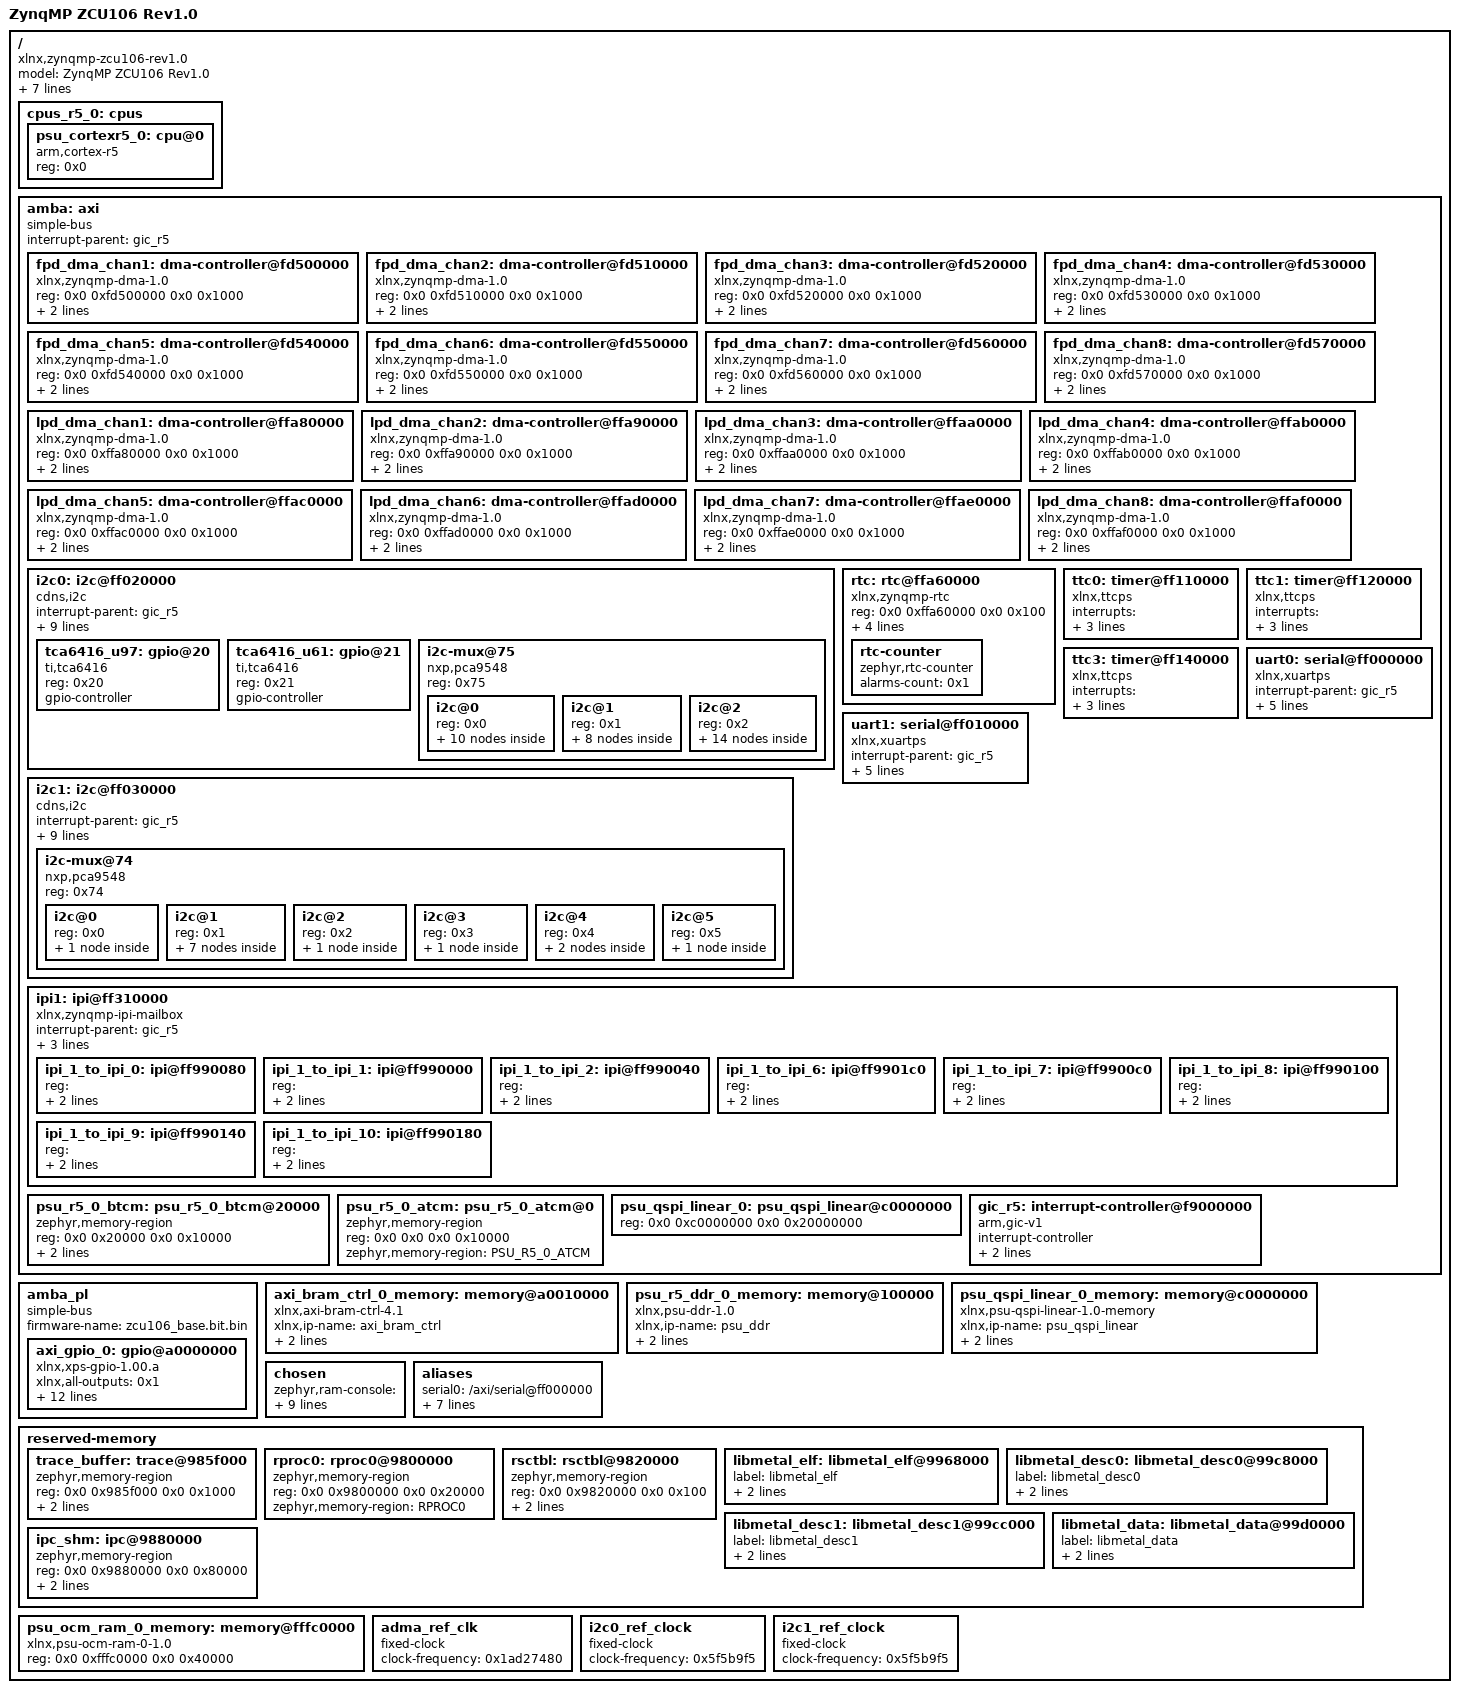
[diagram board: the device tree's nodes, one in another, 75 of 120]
/dts-v1/;
/ {
        compatible = "xlnx,zynqmp-zcu106-rev1.0", "xlnx,zynqmp-zcu106-revA", "xlnx,zynqmp-zcu106", "xlnx,zynqmp";
        #address-cells = <0x2>;
        #size-cells = <0x2>;
        model = "ZynqMP ZCU106 Rev1.0";
        board = "zcu106";
        vivado-version = "2026.2.0";
        device_id = "xczu7ev";
        slrcount = <0x1>;
        family = "ZynqMP";
        speed_grade = "2";
        pruned-sdt = <0x1>;

        cpus_r5_0: cpus {
                phandle = <0xc6>;
                #address-cells = <0x1>;
                #size-cells = <0x0>;

                psu_cortexr5_0: cpu@0 {
                        phandle = <0xc7>;
                        compatible = "arm,cortex-r5", "arm,armv8";
                        device_type = "cpu";
                        reg = <0x0>;
                };
        };

        amba: axi {
                phandle = <0x1>;
                compatible = "simple-bus";
                bootph-all;
                #address-cells = <0x2>;
                #size-cells = <0x2>;
                ranges;
                interrupt-parent = <&gic_r5>;

                fpd_dma_chan1: dma-controller@fd500000 {
                        phandle = <0x43>;
                        compatible = "xlnx,zynqmp-dma-1.0";
                        reg = <0x0 0xfd500000 0x0 0x1000>;
                        interrupts = <0x0 0x7c 0x4 0xa0>;
                        clock-names = "clk_main", "clk_apb";
                        #dma-cells = <0x1>;
                        clocks = <&adma_ref_clk>, <&adma_ref_clk>;
                };

                fpd_dma_chan2: dma-controller@fd510000 {
                        phandle = <0x44>;
                        compatible = "xlnx,zynqmp-dma-1.0";
                        reg = <0x0 0xfd510000 0x0 0x1000>;
                        interrupts = <0x0 0x7d 0x4 0xa0>;
                        clock-names = "clk_main", "clk_apb";
                        #dma-cells = <0x1>;
                        clocks = <&adma_ref_clk>, <&adma_ref_clk>;
                };

                fpd_dma_chan3: dma-controller@fd520000 {
                        phandle = <0x45>;
                        compatible = "xlnx,zynqmp-dma-1.0";
                        reg = <0x0 0xfd520000 0x0 0x1000>;
                        interrupts = <0x0 0x7e 0x4 0xa0>;
                        clock-names = "clk_main", "clk_apb";
                        #dma-cells = <0x1>;
                        clocks = <&adma_ref_clk>, <&adma_ref_clk>;
                };

                fpd_dma_chan4: dma-controller@fd530000 {
                        phandle = <0x46>;
                        compatible = "xlnx,zynqmp-dma-1.0";
                        reg = <0x0 0xfd530000 0x0 0x1000>;
                        interrupts = <0x0 0x7f 0x4 0xa0>;
                        clock-names = "clk_main", "clk_apb";
                        #dma-cells = <0x1>;
                        clocks = <&adma_ref_clk>, <&adma_ref_clk>;
                };

                fpd_dma_chan5: dma-controller@fd540000 {
                        phandle = <0x47>;
                        compatible = "xlnx,zynqmp-dma-1.0";
                        reg = <0x0 0xfd540000 0x0 0x1000>;
                        interrupts = <0x0 0x80 0x4 0xa0>;
                        clock-names = "clk_main", "clk_apb";
                        #dma-cells = <0x1>;
                        clocks = <&adma_ref_clk>, <&adma_ref_clk>;
                };

                fpd_dma_chan6: dma-controller@fd550000 {
                        phandle = <0x48>;
                        compatible = "xlnx,zynqmp-dma-1.0";
                        reg = <0x0 0xfd550000 0x0 0x1000>;
                        interrupts = <0x0 0x81 0x4 0xa0>;
                        clock-names = "clk_main", "clk_apb";
                        #dma-cells = <0x1>;
                        clocks = <&adma_ref_clk>, <&adma_ref_clk>;
                };

                fpd_dma_chan7: dma-controller@fd560000 {
                        phandle = <0x49>;
                        compatible = "xlnx,zynqmp-dma-1.0";
                        reg = <0x0 0xfd560000 0x0 0x1000>;
                        interrupts = <0x0 0x82 0x4 0xa0>;
                        clock-names = "clk_main", "clk_apb";
                        #dma-cells = <0x1>;
                        clocks = <&adma_ref_clk>, <&adma_ref_clk>;
                };

                fpd_dma_chan8: dma-controller@fd570000 {
                        phandle = <0x4a>;
                        compatible = "xlnx,zynqmp-dma-1.0";
                        reg = <0x0 0xfd570000 0x0 0x1000>;
                        interrupts = <0x0 0x83 0x4 0xa0>;
                        clock-names = "clk_main", "clk_apb";
                        #dma-cells = <0x1>;
                        clocks = <&adma_ref_clk>, <&adma_ref_clk>;
                };

                lpd_dma_chan1: dma-controller@ffa80000 {
                        phandle = <0x13>;
                        compatible = "xlnx,zynqmp-dma-1.0";
                        reg = <0x0 0xffa80000 0x0 0x1000>;
                        interrupts = <0x0 0x4d 0x4 0xa0>;
                        clock-names = "clk_main", "clk_apb";
                        #dma-cells = <0x1>;
                        clocks = <&adma_ref_clk>, <&adma_ref_clk>;
                };

                lpd_dma_chan2: dma-controller@ffa90000 {
                        phandle = <0x14>;
                        compatible = "xlnx,zynqmp-dma-1.0";
                        reg = <0x0 0xffa90000 0x0 0x1000>;
                        interrupts = <0x0 0x4e 0x4 0xa0>;
                        clock-names = "clk_main", "clk_apb";
                        #dma-cells = <0x1>;
                        clocks = <&adma_ref_clk>, <&adma_ref_clk>;
                };

                lpd_dma_chan3: dma-controller@ffaa0000 {
                        phandle = <0x15>;
                        compatible = "xlnx,zynqmp-dma-1.0";
                        reg = <0x0 0xffaa0000 0x0 0x1000>;
                        interrupts = <0x0 0x4f 0x4 0xa0>;
                        clock-names = "clk_main", "clk_apb";
                        #dma-cells = <0x1>;
                        clocks = <&adma_ref_clk>, <&adma_ref_clk>;
                };

                lpd_dma_chan4: dma-controller@ffab0000 {
                        phandle = <0x16>;
                        compatible = "xlnx,zynqmp-dma-1.0";
                        reg = <0x0 0xffab0000 0x0 0x1000>;
                        interrupts = <0x0 0x50 0x4 0xa0>;
                        clock-names = "clk_main", "clk_apb";
                        #dma-cells = <0x1>;
                        clocks = <&adma_ref_clk>, <&adma_ref_clk>;
                };

                lpd_dma_chan5: dma-controller@ffac0000 {
                        phandle = <0x17>;
                        compatible = "xlnx,zynqmp-dma-1.0";
                        reg = <0x0 0xffac0000 0x0 0x1000>;
                        interrupts = <0x0 0x51 0x4 0xa0>;
                        clock-names = "clk_main", "clk_apb";
                        #dma-cells = <0x1>;
                        clocks = <&adma_ref_clk>, <&adma_ref_clk>;
                };

                lpd_dma_chan6: dma-controller@ffad0000 {
                        phandle = <0x18>;
                        compatible = "xlnx,zynqmp-dma-1.0";
                        reg = <0x0 0xffad0000 0x0 0x1000>;
                        interrupts = <0x0 0x52 0x4 0xa0>;
                        clock-names = "clk_main", "clk_apb";
                        #dma-cells = <0x1>;
                        clocks = <&adma_ref_clk>, <&adma_ref_clk>;
                };

                lpd_dma_chan7: dma-controller@ffae0000 {
                        phandle = <0x19>;
                        compatible = "xlnx,zynqmp-dma-1.0";
                        reg = <0x0 0xffae0000 0x0 0x1000>;
                        interrupts = <0x0 0x53 0x4 0xa0>;
                        clock-names = "clk_main", "clk_apb";
                        #dma-cells = <0x1>;
                        clocks = <&adma_ref_clk>, <&adma_ref_clk>;
                };

                lpd_dma_chan8: dma-controller@ffaf0000 {
                        phandle = <0x1a>;
                        compatible = "xlnx,zynqmp-dma-1.0";
                        reg = <0x0 0xffaf0000 0x0 0x1000>;
                        interrupts = <0x0 0x54 0x4 0xa0>;
                        clock-names = "clk_main", "clk_apb";
                        #dma-cells = <0x1>;
                        clocks = <&adma_ref_clk>, <&adma_ref_clk>;
                };

                i2c0: i2c@ff020000 {
                        phandle = <0x4d>;
                        compatible = "cdns,i2c";
                        status = "okay";
                        interrupt-parent = <&gic_r5>;
                        interrupts = <0x0 0x11 0x4 0xa0>;
                        clock-frequency = <0x61a80>;
                        reg = <0x0 0xff020000 0x0 0x1000>;
                        #address-cells = <0x1>;
                        #size-cells = <0x0>;
                        fifo-depth = <0x10>;
                        clocks = <&i2c0_ref_clock>;
                        pinctrl-names = "default", "gpio";
                        pinctrl-0 = <0x19>;
                        pinctrl-1 = <0x1a>;
                        scl-gpios = <0xffffffff 0xe 0x6>;
                        sda-gpios = <0xffffffff 0xf 0x6>;

                        tca6416_u97: gpio@20 {
                                phandle = <0x19e>;
                                compatible = "ti,tca6416";
                                reg = <0x20>;
                                gpio-controller;
                                #gpio-cells = <0x2>;
                        };

                        tca6416_u61: gpio@21 {
                                phandle = <0x26>;
                                compatible = "ti,tca6416";
                                reg = <0x21>;
                                gpio-controller;
                                #gpio-cells = <0x2>;
                        };

                        i2c-mux@75 {
                                compatible = "nxp,pca9548";
                                #address-cells = <0x1>;
                                #size-cells = <0x0>;
                                reg = <0x75>;

                                i2c@0 {
                                        #address-cells = <0x1>;
                                        #size-cells = <0x0>;
                                        reg = <0x0>;

                                        u76: ina226@40 {
                                                phandle = <0x19f>;
                                                compatible = "ti,ina226";
                                                #io-channel-cells = <0x1>;
                                                label = "ina226-u76";
                                                reg = <0x40>;
                                                shunt-resistor = <0x1388>;
                                        };

                                        u77: ina226@41 {
                                                phandle = <0x2>;
                                                compatible = "ti,ina226";
                                                #io-channel-cells = <0x1>;
                                                label = "ina226-u77";
                                                reg = <0x41>;
                                                shunt-resistor = <0x1388>;
                                        };

                                        u78: ina226@42 {
                                                phandle = <0x3>;
                                                compatible = "ti,ina226";
                                                #io-channel-cells = <0x1>;
                                                label = "ina226-u78";
                                                reg = <0x42>;
                                                shunt-resistor = <0x1388>;
                                        };

                                        u87: ina226@43 {
                                                phandle = <0x4>;
                                                compatible = "ti,ina226";
                                                #io-channel-cells = <0x1>;
                                                label = "ina226-u87";
                                                reg = <0x43>;
                                                shunt-resistor = <0x1388>;
                                        };

                                        u85: ina226@44 {
                                                phandle = <0x5>;
                                                compatible = "ti,ina226";
                                                #io-channel-cells = <0x1>;
                                                label = "ina226-u85";
                                                reg = <0x44>;
                                                shunt-resistor = <0x1388>;
                                        };

                                        u86: ina226@45 {
                                                phandle = <0x6>;
                                                compatible = "ti,ina226";
                                                #io-channel-cells = <0x1>;
                                                label = "ina226-u86";
                                                reg = <0x45>;
                                                shunt-resistor = <0x1388>;
                                        };

                                        u93: ina226@46 {
                                                phandle = <0x1a0>;
                                                compatible = "ti,ina226";
                                                #io-channel-cells = <0x1>;
                                                label = "ina226-u93";
                                                reg = <0x46>;
                                                shunt-resistor = <0x1388>;
                                        };

                                        u88: ina226@47 {
                                                phandle = <0x8>;
                                                compatible = "ti,ina226";
                                                #io-channel-cells = <0x1>;
                                                label = "ina226-u88";
                                                reg = <0x47>;
                                                shunt-resistor = <0x1388>;
                                        };

                                        u15: ina226@4a {
                                                phandle = <0x1a1>;
                                                compatible = "ti,ina226";
                                                #io-channel-cells = <0x1>;
                                                label = "ina226-u15";
                                                reg = <0x4a>;
                                                shunt-resistor = <0x1388>;
                                        };

                                        u92: ina226@4b {
                                                phandle = <0xa>;
                                                compatible = "ti,ina226";
                                                #io-channel-cells = <0x1>;
                                                label = "ina226-u92";
                                                reg = <0x4b>;
                                                shunt-resistor = <0x1388>;
                                        };
                                };

                                i2c@1 {
                                        #address-cells = <0x1>;
                                        #size-cells = <0x0>;
                                        reg = <0x1>;

                                        u79: ina226@40 {
                                                phandle = <0xb>;
                                                compatible = "ti,ina226";
                                                #io-channel-cells = <0x1>;
                                                label = "ina226-u79";
                                                reg = <0x40>;
                                                shunt-resistor = <0x7d0>;
                                        };

                                        u81: ina226@41 {
                                                phandle = <0xc>;
                                                compatible = "ti,ina226";
                                                #io-channel-cells = <0x1>;
                                                label = "ina226-u81";
                                                reg = <0x41>;
                                                shunt-resistor = <0x1388>;
                                        };

                                        u80: ina226@42 {
                                                phandle = <0xd>;
                                                compatible = "ti,ina226";
                                                #io-channel-cells = <0x1>;
                                                label = "ina226-u80";
                                                reg = <0x42>;
                                                shunt-resistor = <0x1388>;
                                        };

                                        u84: ina226@43 {
                                                phandle = <0xe>;
                                                compatible = "ti,ina226";
                                                #io-channel-cells = <0x1>;
                                                label = "ina226-u84";
                                                reg = <0x43>;
                                                shunt-resistor = <0x1388>;
                                        };

                                        u16: ina226@44 {
                                                phandle = <0xf>;
                                                compatible = "ti,ina226";
                                                #io-channel-cells = <0x1>;
                                                label = "ina226-u16";
                                                reg = <0x44>;
                                                shunt-resistor = <0x1388>;
                                        };

                                        u65: ina226@45 {
                                                phandle = <0x10>;
                                                compatible = "ti,ina226";
                                                #io-channel-cells = <0x1>;
                                                label = "ina226-u65";
                                                reg = <0x45>;
                                                shunt-resistor = <0x1388>;
                                        };

                                        u74: ina226@46 {
                                                phandle = <0x1a2>;
                                                compatible = "ti,ina226";
                                                #io-channel-cells = <0x1>;
                                                label = "ina226-u74";
                                                reg = <0x46>;
                                                shunt-resistor = <0x1388>;
                                        };

                                        u75: ina226@47 {
                                                phandle = <0x12>;
                                                compatible = "ti,ina226";
                                                #io-channel-cells = <0x1>;
                                                label = "ina226-u75";
                                                reg = <0x47>;
                                                shunt-resistor = <0x1388>;
                                        };
                                };

                                i2c@2 {
                                        #address-cells = <0x1>;
                                        #size-cells = <0x0>;
                                        reg = <0x2>;

                                        max15301@a {
                                                compatible = "maxim,max15301";
                                                reg = <0xa>;
                                        };

                                        max15303@b {
                                                compatible = "maxim,max15303";
                                                reg = <0xb>;
                                        };

                                        max15303@10 {
                                                compatible = "maxim,max15303";
                                                reg = <0x10>;
                                        };

                                        max15301@13 {
                                                compatible = "maxim,max15301";
                                                reg = <0x13>;
                                        };

                                        max15303@14 {
                                                compatible = "maxim,max15303";
                                                reg = <0x14>;
                                        };

                                        max15303@15 {
                                                compatible = "maxim,max15303";
                                                reg = <0x15>;
                                        };

                                        max15303@16 {
                                                compatible = "maxim,max15303";
                                                reg = <0x16>;
                                        };

                                        max15303@17 {
                                                compatible = "maxim,max15303";
                                                reg = <0x17>;
                                        };

                                        max15301@18 {
                                                compatible = "maxim,max15301";
                                                reg = <0x18>;
                                        };

                                        max15303@1a {
                                                compatible = "maxim,max15303";
                                                reg = <0x1a>;
                                        };

                                        max15303@1b {
                                                compatible = "maxim,max15303";
                                                reg = <0x1b>;
                                        };

                                        max15303@1d {
                                                compatible = "maxim,max15303";
                                                reg = <0x1d>;
                                        };

                                        max20751@72 {
                                                compatible = "maxim,max20751";
                                                reg = <0x72>;
                                        };

                                        max20751@73 {
                                                compatible = "maxim,max20751";
                                                reg = <0x73>;
                                        };
                                };
                        };
                };

                i2c1: i2c@ff030000 {
                        phandle = <0x4e>;
                        compatible = "cdns,i2c";
                        status = "okay";
                        interrupt-parent = <&gic_r5>;
                        interrupts = <0x0 0x12 0x4 0xa0>;
                        clock-frequency = <0x61a80>;
                        reg = <0x0 0xff030000 0x0 0x1000>;
                        #address-cells = <0x1>;
                        #size-cells = <0x0>;
                        fifo-depth = <0x10>;
                        clocks = <&i2c1_ref_clock>;
                        pinctrl-names = "default", "gpio";
                        pinctrl-0 = <0x1b>;
                        pinctrl-1 = <0x1c>;
                        scl-gpios = <0xffffffff 0x10 0x6>;
                        sda-gpios = <0xffffffff 0x11 0x6>;

                        i2c-mux@74 {
                                compatible = "nxp,pca9548";
                                #address-cells = <0x1>;
                                #size-cells = <0x0>;
                                reg = <0x74>;

                                i2c@0 {
                                        #address-cells = <0x1>;
                                        #size-cells = <0x0>;
                                        reg = <0x0>;

                                        eeprom: eeprom@54 {
                                                phandle = <0x27>;
                                                compatible = "atmel,24c08";
                                                label = "eeprom_zcu106a";
                                                reg = <0x54>;
                                        };
                                };

                                i2c@1 {
                                        #address-cells = <0x1>;
                                        #size-cells = <0x0>;
                                        reg = <0x1>;

                                        si5341: clock-generator@36 {
                                                phandle = <0x1f>;
                                                compatible = "silabs,si5341";
                                                reg = <0x36>;
                                                #clock-cells = <0x2>;
                                                #address-cells = <0x1>;
                                                #size-cells = <0x0>;
                                                clock-names;
                                                clock-output-names = "si5341";

                                                si5341_0: out@0 {
                                                        phandle = <0x28>;
                                                        reg = <0x0>;
                                                        always-on;
                                                };

                                                si5341_2: out@2 {
                                                        phandle = <0x29>;
                                                        reg = <0x2>;
                                                        always-on;
                                                };

                                                si5341_3: out@3 {
                                                        phandle = <0x2a>;
                                                        reg = <0x3>;
                                                        always-on;
                                                };

                                                si5341_6: out@6 {
                                                        phandle = <0x2b>;
                                                        reg = <0x6>;
                                                        always-on;
                                                };

                                                si5341_7: out@7 {
                                                        phandle = <0x2c>;
                                                        reg = <0x7>;
                                                        always-on;
                                                };

                                                si5341_9: out@9 {
                                                        phandle = <0x2d>;
                                                        reg = <0x9>;
                                                        always-on;
                                                };
                                        };
                                };

                                i2c@2 {
                                        #address-cells = <0x1>;
                                        #size-cells = <0x0>;
                                        reg = <0x2>;

                                        si570_1: clock-generator@5d {
                                                phandle = <0x2e>;
                                                #clock-cells = <0x0>;
                                                compatible = "silabs,si570";
                                                reg = <0x5d>;
                                                temperature-stability = <0x32>;
                                                factory-fout = <0x11e1a300>;
                                                clock-frequency = <0x11e1a300>;
                                                clock-output-names = "si570_user";
                                        };
                                };

                                i2c@3 {
                                        #address-cells = <0x1>;
                                        #size-cells = <0x0>;
                                        reg = <0x3>;

                                        si570_2: clock-generator@5d {
                                                phandle = <0x2f>;
                                                #clock-cells = <0x0>;
                                                compatible = "silabs,si570";
                                                reg = <0x5d>;
                                                temperature-stability = <0x32>;
                                                factory-fout = <0x9502f90>;
                                                clock-frequency = <0x9502f90>;
                                                clock-output-names = "si570_mgt";
                                        };
                                };

                                i2c@4 {
                                        #address-cells = <0x1>;
                                        #size-cells = <0x0>;
                                        reg = <0x4>;

                                        si5328: clock-generator@69 {
                                                phandle = <0x30>;
                                                compatible = "silabs,si5328";
                                                reg = <0x69>;
                                                #address-cells = <0x1>;
                                                #size-cells = <0x0>;
                                                #clock-cells = <0x1>;
                                                clock-names;
                                                clock-output-names = "si5328";

                                                si5328_clk: clk0@0 {
                                                        phandle = <0x31>;
                                                        reg = <0x0>;
                                                        clock-frequency = <0x19bfcc0>;
                                                };
                                        };
                                };

                                i2c@5 {
                                        #address-cells = <0x1>;
                                        #size-cells = <0x0>;
                                        reg = <0x5>;

                                        temp@4c {
                                                compatible = "national,lm96163";
                                                reg = <0x4c>;
                                        };
                                };
                        };
                };

                rtc: rtc@ffa60000 {
                        phandle = <0x65>;
                        compatible = "xlnx,zynqmp-rtc";
                        status = "okay";
                        reg = <0x0 0xffa60000 0x0 0x100>;
                        interrupt-parent = <&gic_r5>;
                        interrupts = <0x0 0x1a 0x4 0xa0 0x0 0x1b 0x4 0xa0>;
                        interrupt-names = "alarm", "sec";
                        clock-frequency = <0x8000>;

                        rtc-counter {
                                compatible = "zephyr,rtc-counter";
                                status = "okay";
                                alarms-count = <0x1>;
                        };
                };

                ttc0: timer@ff110000 {
                        phandle = <0x6c>;
                        compatible = "xlnx,ttcps";
                        status = "okay";
                        interrupts = <0x0 0x24 0x4 0xa0 0x0 0x25 0x4 0xa0 0x0 0x26 0x4 0xa0>;
                        reg = <0x0 0xff110000 0x0 0x1000>;
                        interrupt-names = "irq_0", "irq_1", "irq_2";
                        clock-frequency = <0x5f5e100>;
                };

                ttc1: timer@ff120000 {
                        phandle = <0x6d>;
                        compatible = "xlnx,ttcps";
                        status = "okay";
                        interrupts = <0x0 0x27 0x4 0xa0 0x0 0x28 0x4 0xa0 0x0 0x29 0x4 0xa0>;
                        reg = <0x0 0xff120000 0x0 0x1000>;
                        interrupt-names = "irq_0", "irq_1", "irq_2";
                        clock-frequency = <0x5f5e100>;
                };

                ttc3: timer@ff140000 {
                        phandle = <0x6f>;
                        compatible = "xlnx,ttcps";
                        status = "okay";
                        interrupts = <0x0 0x2d 0x4 0xa0 0x0 0x2e 0x4 0xa0 0x0 0x2f 0x4 0xa0>;
                        reg = <0x0 0xff140000 0x0 0x1000>;
                        interrupt-names = "irq_0", "irq_1", "irq_2";
                        clock-frequency = <0x5f5e100>;
                };

                uart0: serial@ff000000 {
                        phandle = <0x70>;
                        compatible = "xlnx,xuartps";
                        interrupt-parent = <&gic_r5>;
                        interrupts = <0x0 0x15 0x4 0xa0>;
                        reg = <0x0 0xff000000 0x0 0x1000>;
                        clock-frequency = <0x5f5b9f5>;
                        current-speed = <0x1c200>;
                        pinctrl-names = "default";
                        pinctrl-0 = <0x21>;
                };

                uart1: serial@ff010000 {
                        phandle = <0x71>;
                        compatible = "xlnx,xuartps";
                        interrupt-parent = <&gic_r5>;
                        interrupts = <0x0 0x16 0x4 0xa0>;
                        reg = <0x0 0xff010000 0x0 0x1000>;
                        clock-frequency = <0x5f5b9f5>;
                        current-speed = <0x1c200>;
                        pinctrl-names = "default";
                        pinctrl-0 = <0x22>;
                };

                ipi1: ipi@ff310000 {
                        phandle = <0x7b>;
                        status = "okay";
                        compatible = "xlnx,zynqmp-ipi-mailbox";
                        interrupt-parent = <&gic_r5>;
                        interrupts = <0x0 0x21 0x4 0xa0>;
                        reg = <0x0 0xff310000 0x0 0x20>;
                        #address-cells = <0x2>;
                        #size-cells = <0x2>;
                        local-ipi-id = <0x1>;
                        reg-names = "host_ipi_reg";

                        ipi_1_to_ipi_0: ipi@ff990080 {
                                phandle = <0x111>;
                                reg = <0x0 0xff990080 0x0 0x20 0x0 0xff9900a0 0x0 0x20 0x0 0xff990400 0x0 0x20 0x0 0xff990420 0x0 0x20>;
                                reg-names = "local_request_region", "local_response_region", "remote_request_region", "remote_response_region";
                                remote-ipi-id = <0x0>;
                        };

                        ipi_1_to_ipi_1: ipi@ff990000 {
                                phandle = <0x112>;
                                reg = <0x0 0xff990000 0x0 0x20 0x0 0xff990020 0x0 0x20 0x0 0xff990000 0x0 0x20 0x0 0xff990020 0x0 0x20>;
                                reg-names = "local_request_region", "local_response_region", "remote_request_region", "remote_response_region";
                                remote-ipi-id = <0x1>;
                        };

                        ipi_1_to_ipi_2: ipi@ff990040 {
                                phandle = <0x113>;
                                reg = <0x0 0xff990040 0x0 0x20 0x0 0xff990060 0x0 0x20 0x0 0xff990200 0x0 0x20 0x0 0xff990220 0x0 0x20>;
                                reg-names = "local_request_region", "local_response_region", "remote_request_region", "remote_response_region";
                                remote-ipi-id = <0x2>;
                        };

                        ipi_1_to_ipi_6: ipi@ff9901c0 {
                                phandle = <0x117>;
                                reg = <0x0 0xff9901c0 0x0 0x20 0x0 0xff9901e0 0x0 0x20 0x0 0xff990e00 0x0 0x20 0x0 0xff990e20 0x0 0x20>;
                                reg-names = "local_request_region", "local_response_region", "remote_request_region", "remote_response_region";
                                remote-ipi-id = <0x3>;
                        };

                        ipi_1_to_ipi_7: ipi@ff9900c0 {
                                phandle = <0x118>;
                                reg = <0x0 0xff9900c0 0x0 0x20 0x0 0xff9900e0 0x0 0x20 0x0 0xff990600 0x0 0x20 0x0 0xff990620 0x0 0x20>;
                                reg-names = "local_request_region", "local_response_region", "remote_request_region", "remote_response_region";
                                remote-ipi-id = <0x7>;
                        };

                        ipi_1_to_ipi_8: ipi@ff990100 {
                                phandle = <0x119>;
                                reg = <0x0 0xff990100 0x0 0x20 0x0 0xff990120 0x0 0x20 0x0 0xff990800 0x0 0x20 0x0 0xff990820 0x0 0x20>;
                                reg-names = "local_request_region", "local_response_region", "remote_request_region", "remote_response_region";
                                remote-ipi-id = <0x8>;
                        };

                        ipi_1_to_ipi_9: ipi@ff990140 {
                                phandle = <0x11a>;
                                reg = <0x0 0xff990140 0x0 0x20 0x0 0xff990160 0x0 0x20 0x0 0xff990a00 0x0 0x20 0x0 0xff990a20 0x0 0x20>;
                                reg-names = "local_request_region", "local_response_region", "remote_request_region", "remote_response_region";
                                remote-ipi-id = <0x9>;
                        };

                        ipi_1_to_ipi_10: ipi@ff990180 {
                                phandle = <0x11b>;
                                reg = <0x0 0xff990180 0x0 0x20 0x0 0xff9901a0 0x0 0x20 0x0 0xff990c00 0x0 0x20 0x0 0xff990c20 0x0 0x20>;
                                reg-names = "local_request_region", "local_response_region", "remote_request_region", "remote_response_region";
                                remote-ipi-id = <0xa>;
                        };
                };

                psu_r5_0_btcm: psu_r5_0_btcm@20000 {
                        phandle = <0x7f>;
                        compatible = "zephyr,memory-region", "xlnx,psu-r5-0-btcm-1.0";
                        status = "okay";
                        reg = <0x0 0x20000 0x0 0x10000>;
                        zephyr,memory-region = "PSU_R5_0_BTCM";
                        zephyr,memory-attr = <0x100000>;
                };

                psu_r5_0_atcm: psu_r5_0_atcm@0 {
                        phandle = <0x7e>;
                        compatible = "zephyr,memory-region", "xlnx,psu-r5-0-atcm-1.0";
                        status = "okay";
                        reg = <0x0 0x0 0x0 0x10000>;
                        zephyr,memory-region = "PSU_R5_0_ATCM";
                };

                psu_qspi_linear_0: psu_qspi_linear@c0000000 {
                        phandle = <0x185>;
                        reg = <0x0 0xc0000000 0x0 0x20000000>;
                };

                gic_r5: interrupt-controller@f9000000  {
                        phandle = <0x81>;
                        status = "okay";
                        interrupt-controller;
                        reg = <0x0 0xf9000000 0x0 0x10000 0x0 0xf9001000 0x0 0x10000>;
                        #interrupt-cells = <0x4>;
                        compatible = "arm,gic-v1", "arm,gic";
                };
        };

        amba_pl: amba_pl {
                phandle = <0x188>;
                ranges;
                compatible = "simple-bus";
                #address-cells = <0x2>;
                #size-cells = <0x2>;
                firmware-name = "zcu106_base.bit.bin";

                axi_gpio_0: gpio@a0000000 {
                        phandle = <0x11>;
                        compatible = "xlnx,xps-gpio-1.00.a";
                        xlnx,all-outputs = <0x1>;
                        #gpio-cells = <0x2>;
                        xlnx,gpio-width = <0x8>;
                        xlnx,dout-default = <0x0>;
                        xlnx,is-dual = <0x0>;
                        xlnx,tri-default-2 = <0xffffffff>;
                        reg = <0x0 0xa0000000 0x0 0x10000>;
                        xlnx,all-inputs-2 = <0x0>;
                        xlnx,all-outputs-2 = <0x0>;
                        gpio-controller;
                        xlnx,dout-default-2 = <0x0>;
                        xlnx,gpio2-width = <0x20>;
                        xlnx,tri-default = <0xffffffff>;
                        xlnx,all-inputs = <0x0>;
                };
        };

        axi_bram_ctrl_0_memory: memory@a0010000 {
                phandle = <0x7>;
                compatible = "xlnx,axi-bram-ctrl-4.1";
                #address-cells = <0x2>;
                xlnx,ip-name = "axi_bram_ctrl";
                device_type = "memory";
                #size-cells = <0x2>;
                memory_type = "memory";
                reg = <0x0 0xa0010000 0x0 0x2000>;
        };

        psu_r5_ddr_0_memory: memory@100000 {
                phandle = <0x7c>;
                compatible = "xlnx,psu-ddr-1.0";
                xlnx,ip-name = "psu_ddr";
                device_type = "memory";
                memory_type = "memory";
                reg = <0x0 0x100000 0x0 0x7fefffff>;
        };

        psu_qspi_linear_0_memory: memory@c0000000 {
                phandle = <0x5d>;
                compatible = "xlnx,psu-qspi-linear-1.0-memory";
                xlnx,ip-name = "psu_qspi_linear";
                device_type = "memory";
                memory_type = "linear_flash";
                reg = <0x0 0xc0000000 0x0 0x20000000>;
        };

        chosen {
                zephyr,ram-console = "/reserved-memory/trace@985f000";
                bootargs = "earlycon console=ttyPS0,115200 clk_ignore_unused init_fatal_sh=1";
                stdout-path = "serial0:115200n8";
                zephyr,ipc_shm = "/reserved-memory/ipc@9880000";
                zephyr,ipc = "/axi/ipi@ff310000/ipi@ff9900c0";
                zephyr,sram = "/axi/psu_r5_0_atcm@0";
                zephyr,console = "serial0";
                zephyr,shell-uart = "serial0";
        };

        aliases {
                serial0 = "/axi/serial@ff000000";
                serial1 = "/axi/serial@ff010000";
                i2c0 = "/axi/i2c@ff020000";
                i2c1 = "/axi/i2c@ff030000";
                rtc0 = "/axi/rtc@ffa60000";
                rtc = "/axi/rtc@ffa60000/rtc-counter";
                nvmem0 = "/axi/i2c@ff030000/i2c-mux@74/i2c@0/eeprom@54";
        };

        reserved-memory {
                ranges;
                #size-cells = <0x2>;
                #address-cells = <0x2>;

                trace_buffer: trace@985f000 {
                        phandle = <0x18f>;
                        reg = <0x0 0x985f000 0x0 0x1000>;
                        compatible = "zephyr,memory-region";
                        zephyr,memory-region = "TRACE_BUFFER";
                        zephyr,memory-attr = <0x200000>;
                };

                rproc0: rproc0@9800000 {
                        phandle = <0x18e>;
                        reg = <0x0 0x9800000 0x0 0x20000>;
                        compatible = "zephyr,memory-region";
                        zephyr,memory-region = "RPROC0";
                };

                rsctbl: rsctbl@9820000 {
                        phandle = <0x190>;
                        reg = <0x0 0x9820000 0x0 0x100>;
                        compatible = "zephyr,memory-region";
                        zephyr,memory-region = "RSCTBL";
                        zephyr,memory-attr = <0x200000>;
                };

                libmetal_elf: libmetal_elf@9968000 {
                        phandle = <0x199>;
                        label = "libmetal_elf";
                        no-map;
                        reg = <0x0 0x9968000 0x0 0x60000>;
                };

                libmetal_desc0: libmetal_desc0@99c8000 {
                        phandle = <0x19a>;
                        label = "libmetal_desc0";
                        no-map;
                        reg = <0x0 0x99c8000 0x0 0x4000>;
                };

                libmetal_desc1: libmetal_desc1@99cc000 {
                        phandle = <0x19b>;
                        label = "libmetal_desc1";
                        no-map;
                        reg = <0x0 0x99cc000 0x0 0x4000>;
                };

                libmetal_data: libmetal_data@99d0000 {
                        phandle = <0x19c>;
                        label = "libmetal_data";
                        no-map;
                        reg = <0x0 0x99d0000 0x0 0x40000>;
                };

                ipc_shm: ipc@9880000 {
                        phandle = <0x19d>;
                        reg = <0x0 0x9880000 0x0 0x80000>;
                        compatible = "zephyr,memory-region", "mmio-sram";
                        status = "okay";
                        zephyr,memory-region = "IPC_SHM";
                        zephyr,memory-attr = <0x200000>;
                };
        };

        psu_ocm_ram_0_memory: memory@fffc0000 {
                phandle = <0x9>;
                compatible = "xlnx,psu-ocm-ram-0-1.0", "mmio-sram";
                reg = <0x0 0xfffc0000 0x0 0x40000>;
        };

        adma_ref_clk: adma_ref_clk {
                compatible = "fixed-clock";
                #clock-cells = <0x0>;
                clock-frequency = <0x1ad27480>;
        };

        i2c0_ref_clock: i2c0_ref_clock {
                compatible = "fixed-clock";
                #clock-cells = <0x0>;
                clock-frequency = <0x5f5b9f5>;
        };

        i2c1_ref_clock: i2c1_ref_clock {
                compatible = "fixed-clock";
                #clock-cells = <0x0>;
                clock-frequency = <0x5f5b9f5>;
        };

        fragment@4 {

                __overlay__ {

                        i2c-mux@75 {

                                i2c@0 {
                                        #address-cells = <0x1>;
                                        #size-cells = <0x0>;
                                        reg = <0x0>;
                                };

                                i2c@1 {
                                        #address-cells = <0x1>;
                                        #size-cells = <0x0>;
                                        reg = <0x1>;
                                };

                                i2c@2 {
                                        #address-cells = <0x1>;
                                        #size-cells = <0x0>;
                                        reg = <0x2>;
                                };

                                i2c@6 {
                                        #address-cells = <0x1>;
                                        #size-cells = <0x0>;
                                        reg = <0x6>;
                                };

                                i2c@7 {
                                        #address-cells = <0x1>;
                                        #size-cells = <0x0>;
                                        reg = <0x7>;
                                };
                        };
                };
        };
};
